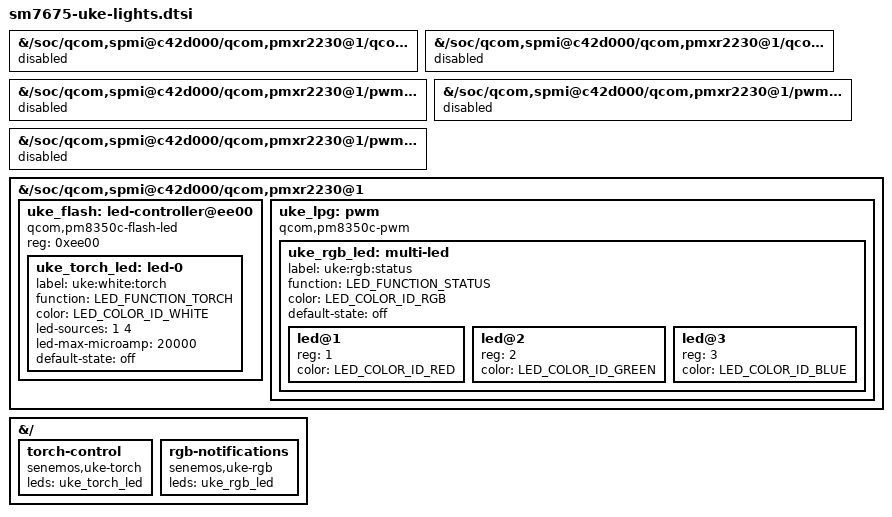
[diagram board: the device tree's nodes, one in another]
// SPDX-License-Identifier: GPL-2.0-only OR BSD-2-Clause
/* Uke OEM DT 94c84aeb and the retained own-device torch-source graph.
 * PMXR2230 shares the reviewed PM8350C flash/LPG register layout.
 * Keep continuous light far below the OEM 250 mA per-channel torch ceiling.
 */
#include <dt-bindings/leds/common.h>

&{/soc/qcom,spmi@c42d000/qcom,pmxr2230@1/qcom,flash_led@ee00} {
	status = "disabled";
};

&{/soc/qcom,spmi@c42d000/qcom,pmxr2230@1/qcom,leds@ef00} {
	status = "disabled";
};

&{/soc/qcom,spmi@c42d000/qcom,pmxr2230@1/pwms@e800} {
	status = "disabled";
};

&{/soc/qcom,spmi@c42d000/qcom,pmxr2230@1/pwms@e900} {
	status = "disabled";
};

&{/soc/qcom,spmi@c42d000/qcom,pmxr2230@1/pwms@eb00} {
	status = "disabled";
};

&{/soc/qcom,spmi@c42d000/qcom,pmxr2230@1} {
	uke_flash: led-controller@ee00 {
		compatible = "qcom,pm8350c-flash-led", "qcom,spmi-flash-led";
		reg = <0xee00>;
		status = "okay";

		uke_torch_led: led-0 {
			label = "uke:white:torch";
			function = LED_FUNCTION_TORCH;
			color = <LED_COLOR_ID_WHITE>;
			led-sources = <1 4>;
			/* Sum for both channels: 10 mA each. No flash/strobe mode. */
			led-max-microamp = <20000>;
			default-state = "off";
		};
	};

	uke_lpg: pwm {
		compatible = "qcom,pm8350c-pwm";
		#pwm-cells = <2>;
		status = "okay";

		uke_rgb_led: multi-led {
			label = "uke:rgb:status";
			function = LED_FUNCTION_STATUS;
			color = <LED_COLOR_ID_RGB>;
			default-state = "off";
			#address-cells = <1>;
			#size-cells = <0>;

			led@1 { reg = <1>; color = <LED_COLOR_ID_RED>; };
			led@2 { reg = <2>; color = <LED_COLOR_ID_GREEN>; };
			led@3 { reg = <3>; color = <LED_COLOR_ID_BLUE>; };
		};
	};
};

&{/} {
	torch-control {
		compatible = "senemos,uke-torch";
		leds = <&uke_torch_led>;
	};

	rgb-notifications {
		compatible = "senemos,uke-rgb";
		leds = <&uke_rgb_led>;
	};
};
